# STM32H745BGT6@M4 register map
File version: 1.0
Registers are 32-bit, access not given, reset 0x0 unless marked. A register's access mark holds for its fields unless they carry their own. Offsets are from the block's base; [hi:lo] are bit positions; {n}, {i} and the like mark numbered series; 'fields as' and 'values as' point back to an identical list.

## RCC
Base 0x58024400
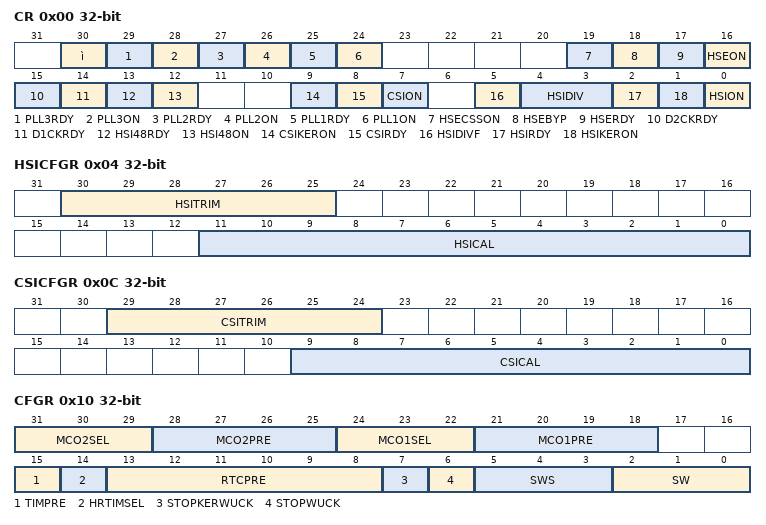
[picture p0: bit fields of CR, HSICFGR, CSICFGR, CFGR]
0x00 CR
  [30] ì, [29] PLL3RDY, [28] PLL3ON, [27] PLL2RDY, [26] PLL2ON, [25] PLL1RDY, [24] PLL1ON, [19] HSECSSON, [18] HSEBYP, [17] HSERDY, [16] HSEON, [15] D2CKRDY, [14] D1CKRDY, [13] HSI48RDY, [12] HSI48ON, [9] CSIKERON, [8] CSIRDY, [7] CSION, [5] HSIDIVF, [4:3] HSIDIV, [2] HSIRDY, [1] HSIKERON, [0] HSION
0x04 HSICFGR
  [30:25] HSITRIM, [11:0] HSICAL
0x08 CRRCR
  [9:0] HSI48CAL
0x0C CSICFGR
  [29:24] CSITRIM, [9:0] CSICAL
0x10 CFGR
  [31:29] MCO2SEL, [28:25] MCO2PRE, [24:22] MCO1SEL, [21:18] MCO1PRE, [15] TIMPRE, [14] HRTIMSEL, [13:8] RTCPRE, [7] STOPKERWUCK, [6] STOPWUCK, [5:3] SWS, [2:0] SW
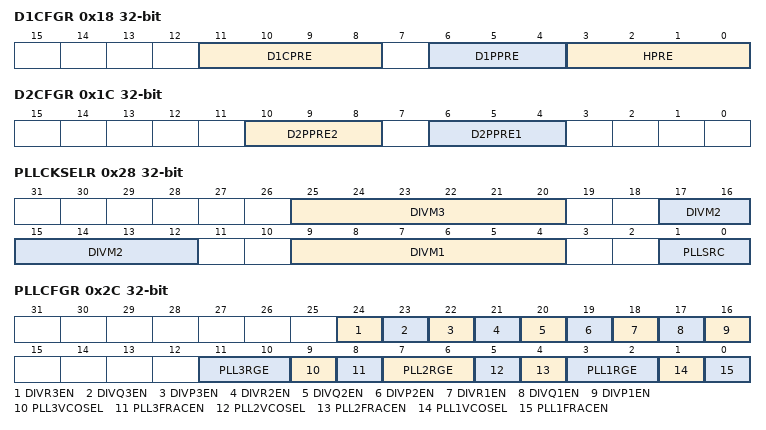
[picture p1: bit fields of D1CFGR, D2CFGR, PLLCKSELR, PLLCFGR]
0x18 D1CFGR
  [11:8] D1CPRE, [6:4] D1PPRE, [3:0] HPRE
0x1C D2CFGR
  [10:8] D2PPRE2, [6:4] D2PPRE1
0x20 D3CFGR
  [6:4] D3PPRE
0x28 PLLCKSELR
  [25:20] DIVM3, [17:12] DIVM2, [9:4] DIVM1, [1:0] PLLSRC
0x2C PLLCFGR
  [24] DIVR3EN, [23] DIVQ3EN, [22] DIVP3EN, [21] DIVR2EN, [20] DIVQ2EN, [19] DIVP2EN, [18] DIVR1EN, [17] DIVQ1EN, [16] DIVP1EN, [11:10] PLL3RGE, [9] PLL3VCOSEL, [8] PLL3FRACEN, [7:6] PLL2RGE, [5] PLL2VCOSEL, [4] PLL2FRACEN, [3:2] PLL1RGE, [1] PLL1VCOSEL, [0] PLL1FRACEN
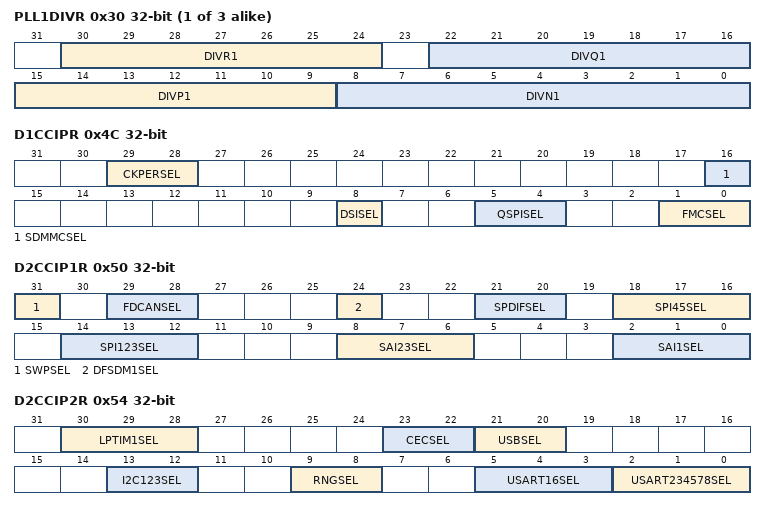
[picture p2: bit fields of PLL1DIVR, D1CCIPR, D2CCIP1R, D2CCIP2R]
{0x28+8i} PLL{i}DIVR (i=1..3)
  [30:24] DIVR{i}, [22:16] DIVQ{i}, [15:9] DIVP{i}, [8:0] DIVN{i}
{0x2C+8i} PLL{i}FRACR (i=1..3)
  [15:3] FRACN{i}
0x4C D1CCIPR
  [29:28] CKPERSEL, [16] SDMMCSEL, [8] DSISEL, [5:4] QSPISEL, [1:0] FMCSEL
0x50 D2CCIP1R
  [31] SWPSEL, [29:28] FDCANSEL, [24] DFSDM1SEL, [21:20] SPDIFSEL, [18:16] SPI45SEL, [14:12] SPI123SEL, [8:6] SAI23SEL, [2:0] SAI1SEL
0x54 D2CCIP2R
  [30:28] LPTIM1SEL, [23:22] CECSEL, [21:20] USBSEL, [13:12] I2C123SEL, [9:8] RNGSEL, [5:3] USART16SEL, [2:0] USART234578SEL
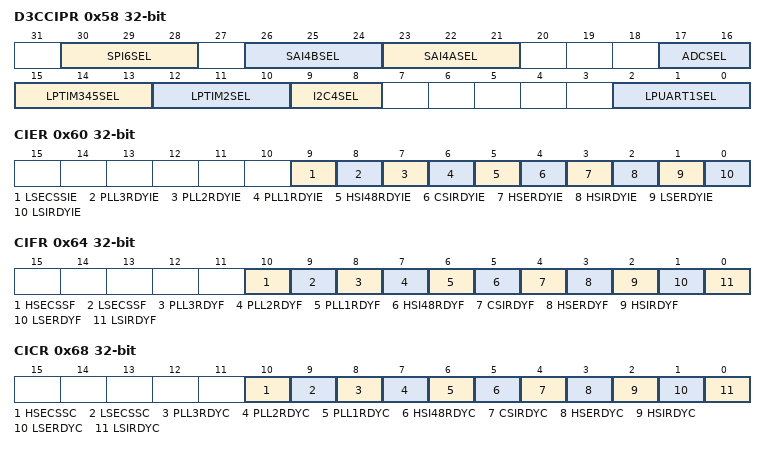
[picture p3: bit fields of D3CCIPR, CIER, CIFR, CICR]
0x58 D3CCIPR
  [30:28] SPI6SEL, [26:24] SAI4BSEL, [23:21] SAI4ASEL, [17:16] ADCSEL, [15:13] LPTIM345SEL, [12:10] LPTIM2SEL, [9:8] I2C4SEL, [2:0] LPUART1SEL
0x60 CIER
  [9] LSECSSIE, [8] PLL3RDYIE, [7] PLL2RDYIE, [6] PLL1RDYIE, [5] HSI48RDYIE, [4] CSIRDYIE, [3] HSERDYIE, [2] HSIRDYIE, [1] LSERDYIE, [0] LSIRDYIE
0x64 CIFR
  [10] HSECSSF, [9] LSECSSF, [8] PLL3RDYF, [7] PLL2RDYF, [6] PLL1RDYF, [5] HSI48RDYF, [4] CSIRDYF, [3] HSERDYF, [2] HSIRDYF, [1] LSERDYF, [0] LSIRDYF
0x68 CICR
  [10] HSECSSC, [9] LSECSSC, [8] PLL3RDYC, [7] PLL2RDYC, [6] PLL1RDYC, [5] HSI48RDYC, [4] CSIRDYC, [3] HSERDYC, [2] HSIRDYC, [1] LSERDYC, [0] LSIRDYC
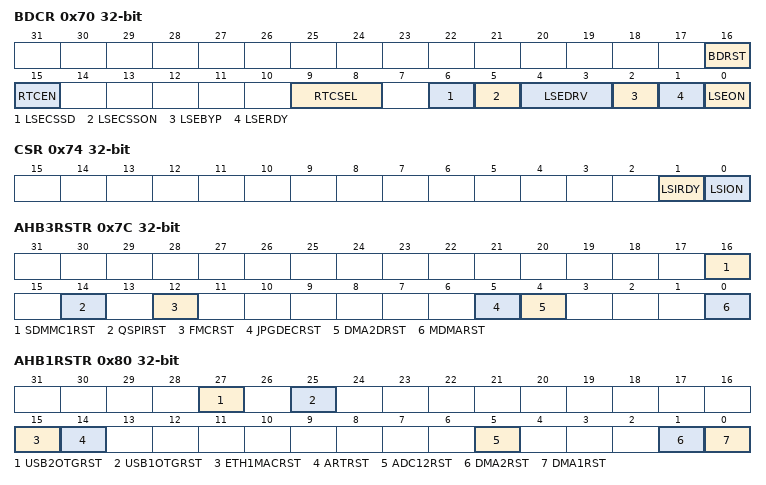
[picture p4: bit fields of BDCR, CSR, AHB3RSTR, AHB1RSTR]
0x70 BDCR
  [16] BDRST, [15] RTCEN, [9:8] RTCSEL, [6] LSECSSD, [5] LSECSSON, [4:3] LSEDRV, [2] LSEBYP, [1] LSERDY, [0] LSEON
0x74 CSR
  [1] LSIRDY, [0] LSION
0x7C AHB3RSTR
  [16] SDMMC1RST, [14] QSPIRST, [12] FMCRST, [5] JPGDECRST, [4] DMA2DRST, [0] MDMARST
0x80 AHB1RSTR
  [27] USB2OTGRST, [25] USB1OTGRST, [15] ETH1MACRST, [14] ARTRST, [5] ADC12RST, [1] DMA2RST, [0] DMA1RST
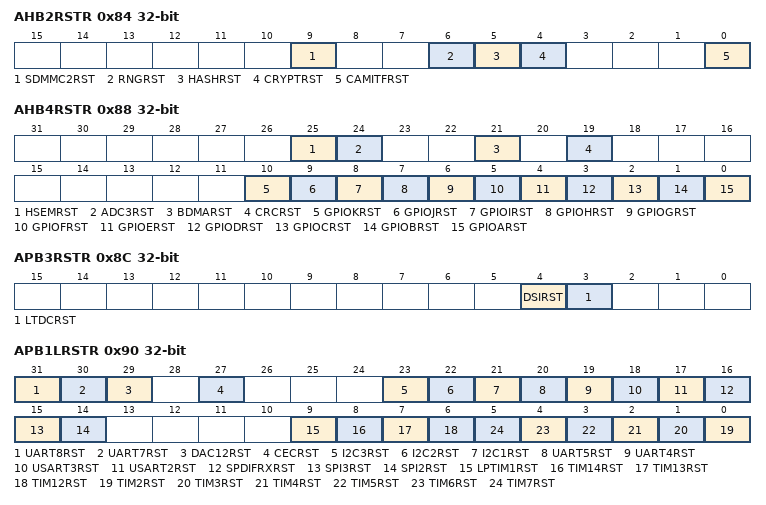
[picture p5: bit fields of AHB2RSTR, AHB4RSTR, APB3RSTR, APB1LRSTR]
0x84 AHB2RSTR
  [9] SDMMC2RST, [6] RNGRST, [5] HASHRST, [4] CRYPTRST, [0] CAMITFRST
0x88 AHB4RSTR
  [25] HSEMRST, [24] ADC3RST, [21] BDMARST, [19] CRCRST, [10] GPIOKRST, [9] GPIOJRST, [8] GPIOIRST, [7] GPIOHRST, [6] GPIOGRST, [5] GPIOFRST, [4] GPIOERST, [3] GPIODRST, [2] GPIOCRST, [1] GPIOBRST, [0] GPIOARST
0x8C APB3RSTR
  [4] DSIRST, [3] LTDCRST
0x90 APB1LRSTR
  [31] UART8RST, [30] UART7RST, [29] DAC12RST, [27] CECRST, [23] I2C3RST, [22] I2C2RST, [21] I2C1RST, [20] UART5RST, [19] UART4RST, [18] USART3RST, [17] USART2RST, [16] SPDIFRXRST, [15] SPI3RST, [14] SPI2RST, [9] LPTIM1RST, [8] TIM14RST, [7] TIM13RST, [6] TIM12RST, [n-2] TIM{n}RST (n=2..7)
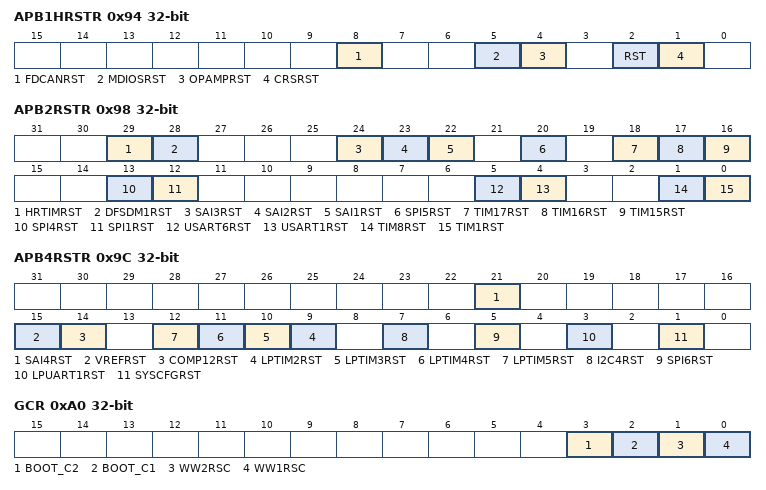
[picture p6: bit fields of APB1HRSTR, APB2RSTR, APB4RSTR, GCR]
0x94 APB1HRSTR
  [8] FDCANRST, [5] MDIOSRST, [4] OPAMPRST, [2] RST, [1] CRSRST
0x98 APB2RSTR
  [29] HRTIMRST, [28] DFSDM1RST, [24] SAI3RST, [23] SAI2RST, [22] SAI1RST, [20] SPI5RST, [18] TIM17RST, [17] TIM16RST, [16] TIM15RST, [13] SPI4RST, [12] SPI1RST, [5] USART6RST, [4] USART1RST, [1] TIM8RST, [0] TIM1RST
0x9C APB4RSTR
  [21] SAI4RST, [15] VREFRST, [14] COMP12RST, [n+7] LPTIM{n}RST (n=2..5), [7] I2C4RST, [5] SPI6RST, [3] LPUART1RST, [1] SYSCFGRST
0xA0 GCR
  [3] BOOT_C2, [2] BOOT_C1, [1] WW2RSC, [0] WW1RSC
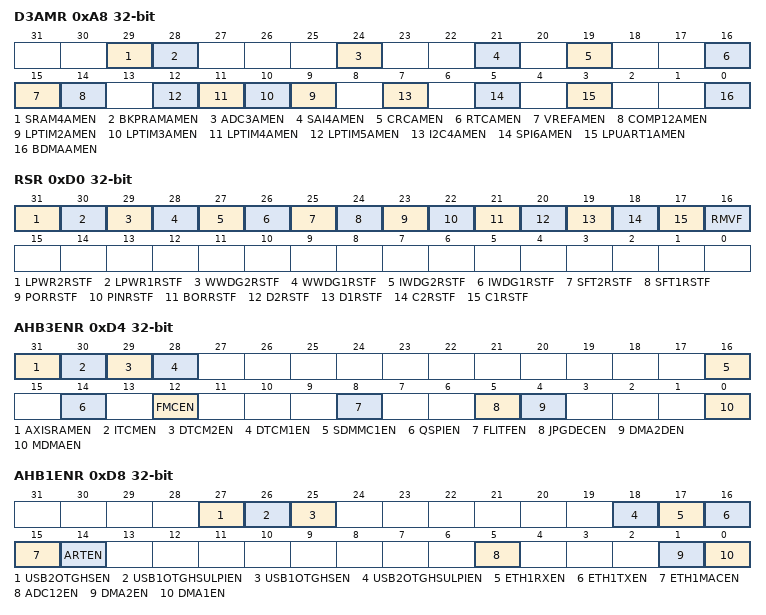
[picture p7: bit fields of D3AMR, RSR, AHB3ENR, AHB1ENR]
0xA8 D3AMR
  [29] SRAM4AMEN, [28] BKPRAMAMEN, [24] ADC3AMEN, [21] SAI4AMEN, [19] CRCAMEN, [16] RTCAMEN, [15] VREFAMEN, [14] COMP12AMEN, [n+7] LPTIM{n}AMEN (n=2..5), [7] I2C4AMEN, [5] SPI6AMEN, [3] LPUART1AMEN, [0] BDMAAMEN
0xD0 RSR
  [31] LPWR2RSTF, [30] LPWR1RSTF, [29] WWDG2RSTF, [28] WWDG1RSTF, [27] IWDG2RSTF, [26] IWDG1RSTF, [25] SFT2RSTF, [24] SFT1RSTF, [23] PORRSTF, [22] PINRSTF, [21] BORRSTF, [20] D2RSTF, [19] D1RSTF, [18] C2RSTF, [17] C1RSTF, [16] RMVF
0xD4 AHB3ENR
  [31] AXISRAMEN, [30] ITCMEN, [29] DTCM2EN, [28] DTCM1EN, [16] SDMMC1EN, [14] QSPIEN, [12] FMCEN, [8] FLITFEN, [5] JPGDECEN, [4] DMA2DEN, [0] MDMAEN
0xD8 AHB1ENR
  [27] USB2OTGHSEN, [26] USB1OTGHSULPIEN, [25] USB1OTGHSEN, [18] USB2OTGHSULPIEN, [17] ETH1RXEN, [16] ETH1TXEN, [15] ETH1MACEN, [14] ARTEN, [5] ADC12EN, [1] DMA2EN, [0] DMA1EN
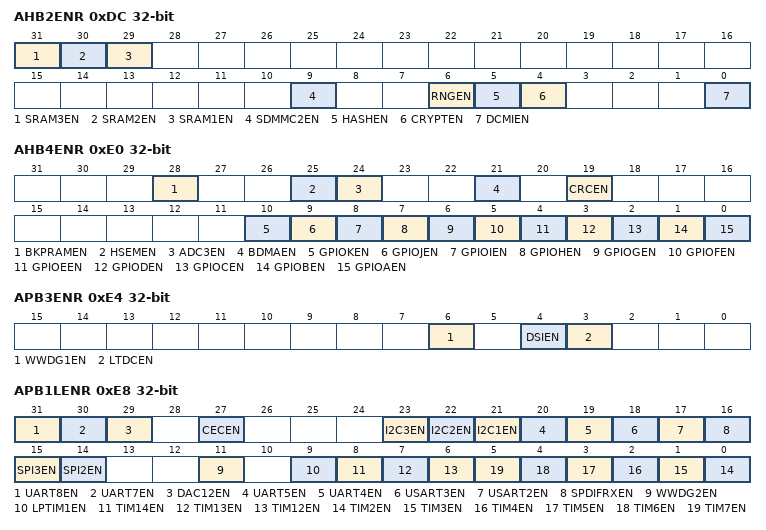
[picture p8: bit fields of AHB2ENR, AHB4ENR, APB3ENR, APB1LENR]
0xDC AHB2ENR
  [31] SRAM3EN, [30] SRAM2EN, [29] SRAM1EN, [9] SDMMC2EN, [6] RNGEN, [5] HASHEN, [4] CRYPTEN, [0] DCMIEN
0xE0 AHB4ENR
  [28] BKPRAMEN, [25] HSEMEN, [24] ADC3EN, [21] BDMAEN, [19] CRCEN, [10] GPIOKEN, [9] GPIOJEN, [8] GPIOIEN, [7] GPIOHEN, [6] GPIOGEN, [5] GPIOFEN, [4] GPIOEEN, [3] GPIODEN, [2] GPIOCEN, [1] GPIOBEN, [0] GPIOAEN
0xE4 APB3ENR
  [6] WWDG1EN, [4] DSIEN, [3] LTDCEN
0xE8 APB1LENR
  [31] UART8EN, [30] UART7EN, [29] DAC12EN, [27] CECEN, [23] I2C3EN, [22] I2C2EN, [21] I2C1EN, [20] UART5EN, [19] UART4EN, [18] USART3EN, [17] USART2EN, [16] SPDIFRXEN, [15] SPI3EN, [14] SPI2EN, [11] WWDG2EN, [9] LPTIM1EN, [8] TIM14EN, [7] TIM13EN, [6] TIM12EN, [n-2] TIM{n}EN (n=2..7)
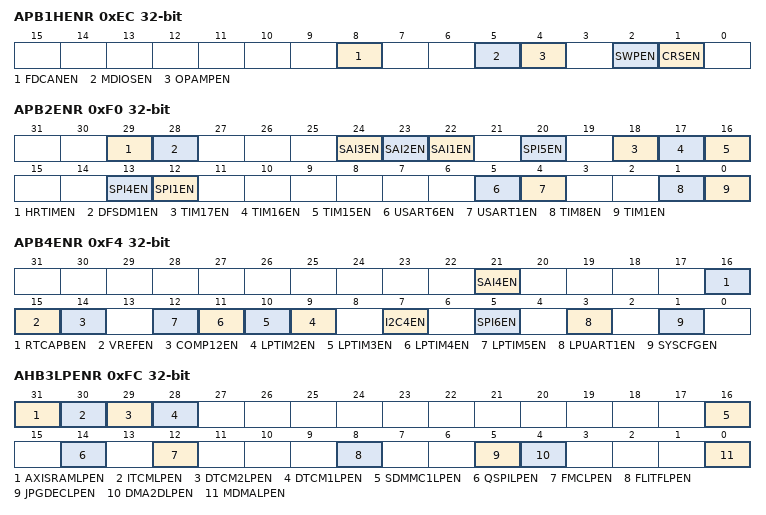
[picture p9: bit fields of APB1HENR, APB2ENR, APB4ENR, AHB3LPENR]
0xEC APB1HENR
  [8] FDCANEN, [5] MDIOSEN, [4] OPAMPEN, [2] SWPEN, [1] CRSEN
0xF0 APB2ENR
  [29] HRTIMEN, [28] DFSDM1EN, [24] SAI3EN, [23] SAI2EN, [22] SAI1EN, [20] SPI5EN, [18] TIM17EN, [17] TIM16EN, [16] TIM15EN, [13] SPI4EN, [12] SPI1EN, [5] USART6EN, [4] USART1EN, [1] TIM8EN, [0] TIM1EN
0xF4 APB4ENR
  [21] SAI4EN, [16] RTCAPBEN, [15] VREFEN, [14] COMP12EN, [n+7] LPTIM{n}EN (n=2..5), [7] I2C4EN, [5] SPI6EN, [3] LPUART1EN, [1] SYSCFGEN
0xFC AHB3LPENR
  [31] AXISRAMLPEN, [30] ITCMLPEN, [29] DTCM2LPEN, [28] DTCM1LPEN, [16] SDMMC1LPEN, [14] QSPILPEN, [12] FMCLPEN, [8] FLITFLPEN, [5] JPGDECLPEN, [4] DMA2DLPEN, [0] MDMALPEN
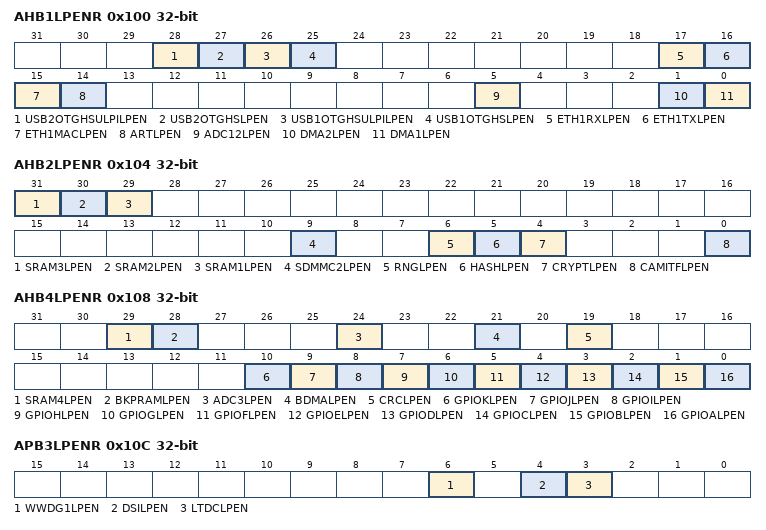
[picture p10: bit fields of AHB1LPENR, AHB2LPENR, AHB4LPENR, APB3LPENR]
0x100 AHB1LPENR
  [28] USB2OTGHSULPILPEN, [27] USB2OTGHSLPEN, [26] USB1OTGHSULPILPEN, [25] USB1OTGHSLPEN, [17] ETH1RXLPEN, [16] ETH1TXLPEN, [15] ETH1MACLPEN, [14] ARTLPEN, [5] ADC12LPEN, [1] DMA2LPEN, [0] DMA1LPEN
0x104 AHB2LPENR
  [31] SRAM3LPEN, [30] SRAM2LPEN, [29] SRAM1LPEN, [9] SDMMC2LPEN, [6] RNGLPEN, [5] HASHLPEN, [4] CRYPTLPEN, [0] CAMITFLPEN
0x108 AHB4LPENR
  [29] SRAM4LPEN, [28] BKPRAMLPEN, [24] ADC3LPEN, [21] BDMALPEN, [19] CRCLPEN, [10] GPIOKLPEN, [9] GPIOJLPEN, [8] GPIOILPEN, [7] GPIOHLPEN, [6] GPIOGLPEN, [5] GPIOFLPEN, [4] GPIOELPEN, [3] GPIODLPEN, [2] GPIOCLPEN, [1] GPIOBLPEN, [0] GPIOALPEN
0x10C APB3LPENR
  [6] WWDG1LPEN, [4] DSILPEN, [3] LTDCLPEN
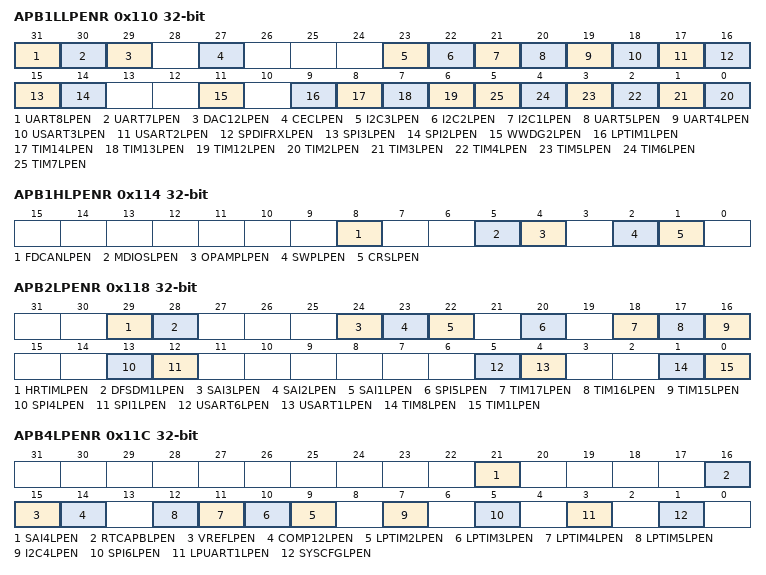
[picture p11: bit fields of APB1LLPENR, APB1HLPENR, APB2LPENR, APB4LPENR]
0x110 APB1LLPENR
  [31] UART8LPEN, [30] UART7LPEN, [29] DAC12LPEN, [27] CECLPEN, [23] I2C3LPEN, [22] I2C2LPEN, [21] I2C1LPEN, [20] UART5LPEN, [19] UART4LPEN, [18] USART3LPEN, [17] USART2LPEN, [16] SPDIFRXLPEN, [15] SPI3LPEN, [14] SPI2LPEN, [11] WWDG2LPEN, [9] LPTIM1LPEN, [8] TIM14LPEN, [7] TIM13LPEN, [6] TIM12LPEN, [n-2] TIM{n}LPEN (n=2..7)
0x114 APB1HLPENR
  [8] FDCANLPEN, [5] MDIOSLPEN, [4] OPAMPLPEN, [2] SWPLPEN, [1] CRSLPEN
0x118 APB2LPENR
  [29] HRTIMLPEN, [28] DFSDM1LPEN, [24] SAI3LPEN, [23] SAI2LPEN, [22] SAI1LPEN, [20] SPI5LPEN, [18] TIM17LPEN, [17] TIM16LPEN, [16] TIM15LPEN, [13] SPI4LPEN, [12] SPI1LPEN, [5] USART6LPEN, [4] USART1LPEN, [1] TIM8LPEN, [0] TIM1LPEN
0x11C APB4LPENR
  [21] SAI4LPEN, [16] RTCAPBLPEN, [15] VREFLPEN, [14] COMP12LPEN, [n+7] LPTIM{n}LPEN (n=2..5), [7] I2C4LPEN, [5] SPI6LPEN, [3] LPUART1LPEN, [1] SYSCFGLPEN
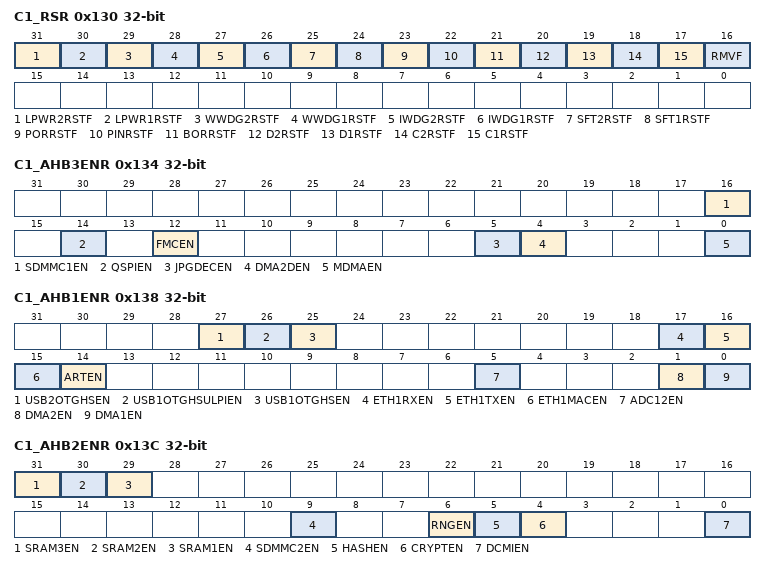
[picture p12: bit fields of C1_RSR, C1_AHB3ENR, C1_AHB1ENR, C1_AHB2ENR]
0x130 C1_RSR
  fields as RSR
0x134 C1_AHB3ENR
  [16] SDMMC1EN, [14] QSPIEN, [12] FMCEN, [5] JPGDECEN, [4] DMA2DEN, [0] MDMAEN
0x138 C1_AHB1ENR
  [27] USB2OTGHSEN, [26] USB1OTGHSULPIEN, [25] USB1OTGHSEN, [17] ETH1RXEN, [16] ETH1TXEN, [15] ETH1MACEN, [14] ARTEN, [5] ADC12EN, [1] DMA2EN, [0] DMA1EN
0x13C C1_AHB2ENR
  fields as AHB2ENR
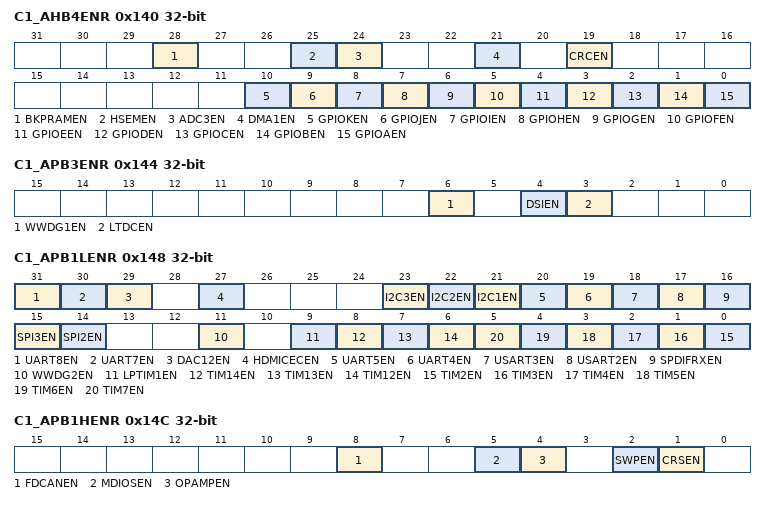
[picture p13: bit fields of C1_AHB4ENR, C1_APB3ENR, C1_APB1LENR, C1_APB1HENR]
0x140 C1_AHB4ENR
  [28] BKPRAMEN, [25] HSEMEN, [24] ADC3EN, [21] DMA1EN, [19] CRCEN, [10] GPIOKEN, [9] GPIOJEN, [8] GPIOIEN, [7] GPIOHEN, [6] GPIOGEN, [5] GPIOFEN, [4] GPIOEEN, [3] GPIODEN, [2] GPIOCEN, [1] GPIOBEN, [0] GPIOAEN
0x144 C1_APB3ENR
  [6] WWDG1EN, [4] DSIEN, [3] LTDCEN
0x148 C1_APB1LENR
  [31] UART8EN, [30] UART7EN, [29] DAC12EN, [27] HDMICECEN, [23] I2C3EN, [22] I2C2EN, [21] I2C1EN, [20] UART5EN, [19] UART4EN, [18] USART3EN, [17] USART2EN, [16] SPDIFRXEN, [15] SPI3EN, [14] SPI2EN, [11] WWDG2EN, [9] LPTIM1EN, [8] TIM14EN, [7] TIM13EN, [6] TIM12EN, [n-2] TIM{n}EN (n=2..7)
0x14C C1_APB1HENR
  [8] FDCANEN, [5] MDIOSEN, [4] OPAMPEN, [2] SWPEN, [1] CRSEN
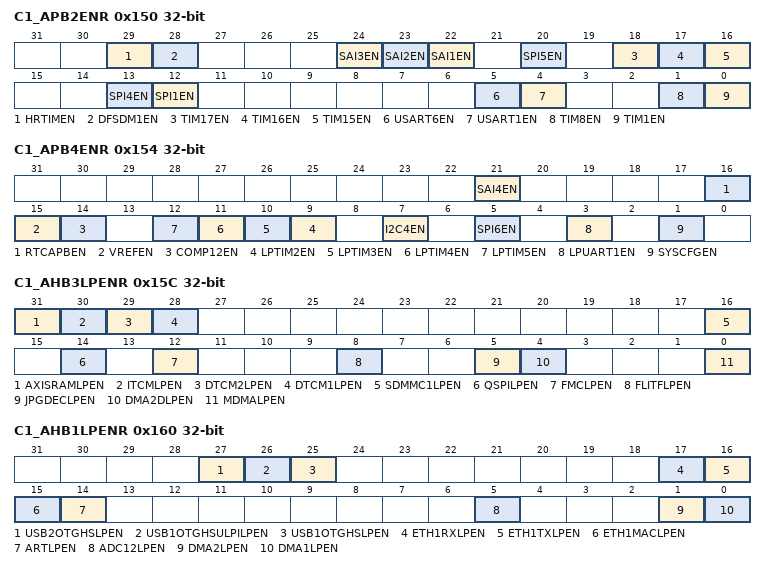
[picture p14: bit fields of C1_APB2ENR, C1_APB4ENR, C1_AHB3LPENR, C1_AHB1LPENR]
0x150 C1_APB2ENR
  fields as APB2ENR
0x154 C1_APB4ENR
  fields as APB4ENR
0x15C C1_AHB3LPENR
  fields as AHB3LPENR
0x160 C1_AHB1LPENR
  [27] USB2OTGHSLPEN, [26] USB1OTGHSULPILPEN, [25] USB1OTGHSLPEN, [17] ETH1RXLPEN, [16] ETH1TXLPEN, [15] ETH1MACLPEN, [14] ARTLPEN, [5] ADC12LPEN, [1] DMA2LPEN, [0] DMA1LPEN
0x164 C1_AHB2LPENR
  fields as AHB2LPENR
0x168 C1_AHB4LPENR
  [29] SRAM4LPEN, [28] BKPRAMLPEN, [24] ADC3LPEN, [21] DMA1LPEN, [19] CRCLPEN, [10] GPIOKLPEN, [9] GPIOJLPEN, [8] GPIOILPEN, [7] GPIOHLPEN, [6] GPIOGLPEN, [5] GPIOFLPEN, [4] GPIOELPEN, [3] GPIODLPEN, [2] GPIOCLPEN, [1] GPIOBLPEN, [0] GPIOALPEN
0x16C C1_APB3LPENR
  [6] WWDG1LPEN, [4] DSILPEN, [3] LTDCLPEN
0x170 C1_APB1LLPENR
  fields as APB1LLPENR
0x174 C1_APB1HLPENR
  fields as APB1HLPENR
0x178 C1_APB2LPENR
  [29] HRTIMLPEN, [28] DFSDM1LPEN, [24] SA3LPEN, [23] SAI2LPEN, [22] SAI1LPEN, [20] SPI5LPEN, [18] TIM17LPEN, [17] TIM16LPEN, [16] TIM15LPEN, [13] SPI4LPEN, [12] SPI1LPEN, [5] USART6LPEN, [4] USART1LPEN, [1] TIM8LPEN, [0] TIM1LPEN
0x17C C1_APB4LPENR
  fields as APB4LPENR
0x190 C2_RSR
  fields as RSR
0x194 C2_AHB3ENR
  fields as AHB3ENR
0x198 C2_AHB1ENR
  fields as C1_AHB1ENR
0x19C C2_AHB2ENR
  [9] SDMMC2EN, [6] RNGEN, [5] HASHEN, [4] CRYPTEN, [0] DCMIEN
0x1A0 C2_AHB4ENR
  fields as C1_AHB4ENR
0x1A4 C2_APB3ENR
  [6] WWDG1EN, [4] DSIEN, [3] LTDCEN
0x1A8 C2_APB1LENR
  fields as C1_APB1LENR
0x1AC C2_APB1HENR
  [8] FDCANEN, [5] MDIOSEN, [4] OPAMPEN, [2] SWPEN, [1] CRSEN
0x1B0 C2_APB2ENR
  fields as APB2ENR
0x1B4 C2_APB4ENR
  fields as APB4ENR
0x1BC C2_AHB3LPENR
  [31] AXISRAMLPEN, [30] ITCMLPEN, [29] DTCM2LPEN, [16] SDMMC1LPEN, [14] QSPILPEN, [12] FMCLPEN, [8] FLITFLPEN, [5] JPGDECLPEN, [4] DMA2DLPEN, [0] MDMALPEN
0x1C0 C2_AHB1LPENR
  fields as C1_AHB1LPENR
0x1C4 C2_AHB2LPENR
  fields as AHB2LPENR
0x1C8 C2_AHB4LPENR
  fields as C1_AHB4LPENR
0x1CC C2_APB3LPENR
  [6] WWDG1LPEN, [4] DSILPEN, [3] LTDCLPEN
0x1D0 C2_APB1LLPENR
  fields as APB1LLPENR
0x1D4 C2_APB1HLPENR
  fields as APB1HLPENR
0x1D8 C2_APB2LPENR
  fields as APB2LPENR
0x1DC C2_APB4LPENR
  fields as APB4LPENR
